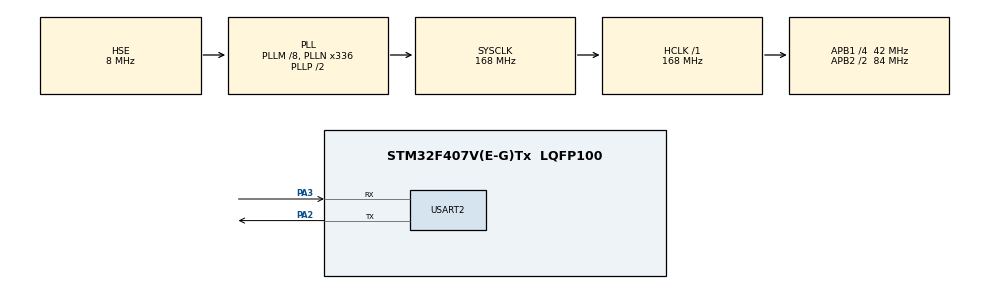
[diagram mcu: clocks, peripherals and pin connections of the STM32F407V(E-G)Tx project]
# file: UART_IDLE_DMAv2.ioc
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Dma.Request0=USART2_RX
Dma.Request1=USART2_TX
Dma.USART2_RX.0.Direction=DMA_PERIPH_TO_MEMORY
Dma.USART2_RX.0.FIFOMode=DMA_FIFOMODE_DISABLE
Dma.USART2_RX.0.Instance=DMA1_Stream5
Dma.USART2_RX.0.MemDataAlignment=DMA_MDATAALIGN_BYTE
Dma.USART2_RX.0.MemInc=DMA_MINC_ENABLE
Dma.USART2_RX.0.Mode=DMA_CIRCULAR
Dma.USART2_RX.0.PeriphDataAlignment=DMA_PDATAALIGN_BYTE
Dma.USART2_RX.0.PeriphInc=DMA_PINC_DISABLE
Dma.USART2_RX.0.Priority=DMA_PRIORITY_LOW
Dma.USART2_TX.1.Direction=DMA_MEMORY_TO_PERIPH
Dma.USART2_TX.1.FIFOMode=DMA_FIFOMODE_DISABLE
Dma.USART2_TX.1.Instance=DMA1_Stream6
Dma.USART2_TX.1.MemDataAlignment=DMA_MDATAALIGN_BYTE
Dma.USART2_TX.1.MemInc=DMA_MINC_ENABLE
Dma.USART2_TX.1.Mode=DMA_NORMAL
Dma.USART2_TX.1.PeriphDataAlignment=DMA_PDATAALIGN_BYTE
Dma.USART2_TX.1.PeriphInc=DMA_PINC_DISABLE
Dma.USART2_TX.1.Priority=DMA_PRIORITY_LOW
FREERTOS.Tasks01=defaultTask,24,128,StartDefaultTask,Default,NULL,Dynamic,NULL,NULL
FREERTOS.configUSE_NEWLIB_REENTRANT=1
Mcu.Family=STM32F4
Mcu.Name=STM32F407V(E-G)Tx
Mcu.Package=LQFP100
NVIC.DMA1_Stream5_IRQn=true\:5\:0\:false\:false\:true\:true\:false\:true\:true
NVIC.DMA1_Stream6_IRQn=true\:5\:0\:false\:false\:true\:true\:false\:true\:true
NVIC.PriorityGroup=NVIC_PRIORITYGROUP_4
NVIC.TIM6_DAC_IRQn=true\:15\:0\:false\:false\:true\:false\:false\:true\:true
NVIC.TimeBase=TIM6_DAC_IRQn
NVIC.TimeBaseIP=TIM6
NVIC.USART2_IRQn=true\:5\:0\:false\:false\:true\:true\:true\:true\:true
PA13.Mode=Serial_Wire
PA13.Signal=SYS_JTMS-SWDIO
PA14.Mode=Serial_Wire
PA14.Signal=SYS_JTCK-SWCLK
PA2.Mode=Asynchronous
PA2.Signal=USART2_TX
PA3.Mode=Asynchronous
PA3.Signal=USART2_RX
PH0-OSC_IN.Mode=HSE-External-Oscillator
PH0-OSC_IN.Signal=RCC_OSC_IN
PH1-OSC_OUT.Mode=HSE-External-Oscillator
PH1-OSC_OUT.Signal=RCC_OSC_OUT
ProjectManager.HeapSize=0x200
ProjectManager.StackSize=0x400
ProjectManager.TargetToolchain=STM32CubeIDE
RCC.48MHZClocksFreq_Value=48000000
RCC.AHBFreq_Value=168000000
RCC.APB1CLKDivider=RCC_HCLK_DIV4
RCC.APB1Freq_Value=42000000
RCC.APB1TimFreq_Value=84000000
RCC.APB2CLKDivider=RCC_HCLK_DIV2
RCC.APB2Freq_Value=84000000
RCC.APB2TimFreq_Value=168000000
RCC.CortexFreq_Value=168000000
RCC.HCLKFreq_Value=168000000
RCC.HSE_VALUE=8000000
RCC.HSI_VALUE=16000000
RCC.LSE_VALUE=32768
RCC.PLLM=8
RCC.PLLN=336
RCC.PLLQ=7
RCC.PLLSourceVirtual=RCC_PLLSOURCE_HSE
RCC.SYSCLKFreq_VALUE=168000000
RCC.SYSCLKSource=RCC_SYSCLKSOURCE_PLLCLK
RCC.VCOOutputFreq_Value=336000000
USART2.VirtualMode=VM_ASYNC
VP_FREERTOS_VS_CMSIS_V2.Mode=CMSIS_V2
VP_SYS_VS_tim6.Mode=TIM6
board=STM32F407G-DISC1

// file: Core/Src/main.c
/* USER CODE BEGIN Header */
/**
  ******************************************************************************
  * @file           : main.c
  * @brief          : Main program body
  ******************************************************************************
  * @attention
  *
  * Copyright (c) 2026 STMicroelectronics.
  * All rights reserved.
  *
  * This software is licensed under terms that can be found in the LICENSE file
  * in the root directory of this software component.
  * If no LICENSE file comes with this software, it is provided AS-IS.
  *
  ******************************************************************************
  */
/* USER CODE END Header */
#include "main.h"
#include "cmsis_os.h"

/* USER CODE BEGIN Includes */
#include "uart_comm.h"
#include "app_protocol.h"
#include "protocol_uart.h"
#ifdef UART_COMM_TEST
#include "uart_comm_internal.h"
#include "tests.h"
#include "uart_comm_tests.h"
#include "uart_rtos_tests.h"
#endif
/* USER CODE END Includes */

UART_HandleTypeDef huart2;
DMA_HandleTypeDef hdma_usart2_rx;
DMA_HandleTypeDef hdma_usart2_tx;

/* Definitions for defaultTask */
osThreadId_t defaultTaskHandle;
const osThreadAttr_t defaultTask_attributes = {
  .name = "defaultTask",
  .stack_size = 128 * 4,
  .priority = (osPriority_t) osPriorityNormal,
};
/* USER CODE BEGIN PV */
uart_comm_tx_result_t uart_last_tx_result;
uint32_t uart_tx_result_count;
#ifdef UART_COMM_TEST
HAL_StatusTypeDef rx_start_status;
#endif
/* USER CODE END PV */

void SystemClock_Config(void);
static void MX_GPIO_Init(void);
static void MX_DMA_Init(void);
static void MX_USART2_UART_Init(void);
void StartDefaultTask(void *argument);

/* USER CODE BEGIN 0 */
#ifndef UART_COMM_TEST
/* Iki handler da UART taskinda calisir: kisa tut, bekleme yapma. */
static void on_tx_result(const uart_comm_tx_result_t *result, void *user)
{
    (void)user;
    uart_last_tx_result = *result;
    uart_tx_result_count++;
}
static protocol_uart_t uart_protocol;
static const uart_comm_handlers_t uart_handlers = {
    .on_rx = protocol_uart_on_rx, .on_tx_result = on_tx_result, .rx_user = &uart_protocol
};
#endif
/* Proje HAL callback'lerinin sahibi; diger UART'lar burada yonlendirilebilir. */
void HAL_UARTEx_RxEventCallback(UART_HandleTypeDef *uart, uint16_t size) { uart_comm_on_rx_event(uart, size); }
void HAL_UART_ErrorCallback(UART_HandleTypeDef *uart) { uart_comm_on_error(uart); }
void HAL_UART_AbortReceiveCpltCallback(UART_HandleTypeDef *uart) { uart_comm_on_rx_abort_complete(uart); }
void HAL_UART_TxCpltCallback(UART_HandleTypeDef *uart) { uart_comm_on_tx_complete(uart); }
void HAL_UART_AbortTransmitCpltCallback(UART_HandleTypeDef *uart) { uart_comm_on_tx_abort_complete(uart); }
/* USER CODE END 0 */

int main(void)
{

  /* MCU Configuration--------------------------------------------------------*/

  /* Reset of all peripherals, Initializes the Flash interface and the Systick. */
  HAL_Init();

  /* Configure the system clock */
  SystemClock_Config();

  /* Initialize all configured peripherals */
  MX_GPIO_Init();
  MX_DMA_Init();
  MX_USART2_UART_Init();
  /* USER CODE BEGIN 2 */
#if defined(UART_COMM_TEST) && !defined(UART_COMM_SERIAL_TEST)
  /* Eski cekirdek regresyonu scheduler oncesi; uretimde bu kapilar yok. */
  birim_testleri_kosur();
  app_protocol_init();
  test_rx_set_handler(app_protocol_on_frame, NULL);
  rx_start_status = rx_start(&huart2);
  if (tx_init(&huart2) != HAL_OK) Error_Handler();
  loopback_testi_kosur(&huart2);
  uart_comm_tests_run(&huart2);
  comm_test_stop_before_scheduler();
#endif
  app_protocol_init();
#ifndef UART_COMM_TEST
  protocol_uart_init(&uart_protocol, app_protocol_on_frame, NULL);
#endif
/* USER CODE END 2 */

  /* Init scheduler */
  osKernelInitialize();

  /* Create the thread(s) */
  /* creation of defaultTask */
  defaultTaskHandle = osThreadNew(StartDefaultTask, NULL, &defaultTask_attributes);

  /* USER CODE BEGIN RTOS_THREADS */
#ifdef UART_COMM_SERIAL_TEST
  uart_serial_test_init_handlers();
  if (uart_comm_init(&huart2, &uart_serial_test_handlers) != HAL_OK) Error_Handler();
#elif defined(UART_COMM_TEST)
  uart_rtos_test_init_handlers();
  if (uart_comm_init(&huart2, &uart_rtos_test_handlers) != HAL_OK) Error_Handler();
#else
  if (uart_comm_init(&huart2, &uart_handlers) != HAL_OK) Error_Handler();
#endif
/* USER CODE END RTOS_THREADS */

  /* Start scheduler */
  osKernelStart();

  /* We should never get here as control is now taken by the scheduler */

  /* Infinite loop */
  while (1)
  {

  /* USER CODE BEGIN 3 */
  Error_Handler();
  }
/* USER CODE END 3 */
}

void SystemClock_Config(void)
{
  RCC_OscInitTypeDef RCC_OscInitStruct = {0};
  RCC_ClkInitTypeDef RCC_ClkInitStruct = {0};

  /** Configure the main internal regulator output voltage
  */
  __HAL_RCC_PWR_CLK_ENABLE();
  __HAL_PWR_VOLTAGESCALING_CONFIG(PWR_REGULATOR_VOLTAGE_SCALE1);

  /** Initializes the RCC Oscillators according to the specified parameters
  * in the RCC_OscInitTypeDef structure.
  */
  RCC_OscInitStruct.OscillatorType = RCC_OSCILLATORTYPE_HSE;
  RCC_OscInitStruct.HSEState = RCC_HSE_ON;
  RCC_OscInitStruct.PLL.PLLState = RCC_PLL_ON;
  RCC_OscInitStruct.PLL.PLLSource = RCC_PLLSOURCE_HSE;
  RCC_OscInitStruct.PLL.PLLM = 8;
  RCC_OscInitStruct.PLL.PLLN = 336;
  RCC_OscInitStruct.PLL.PLLP = RCC_PLLP_DIV2;
  RCC_OscInitStruct.PLL.PLLQ = 7;
  if (HAL_RCC_OscConfig(&RCC_OscInitStruct) != HAL_OK)
  {
    Error_Handler();
  }

  /** Initializes the CPU, AHB and APB buses clocks
  */
  RCC_ClkInitStruct.ClockType = RCC_CLOCKTYPE_HCLK|RCC_CLOCKTYPE_SYSCLK
                              |RCC_CLOCKTYPE_PCLK1|RCC_CLOCKTYPE_PCLK2;
  RCC_ClkInitStruct.SYSCLKSource = RCC_SYSCLKSOURCE_PLLCLK;
  RCC_ClkInitStruct.AHBCLKDivider = RCC_SYSCLK_DIV1;
  RCC_ClkInitStruct.APB1CLKDivider = RCC_HCLK_DIV4;
  RCC_ClkInitStruct.APB2CLKDivider = RCC_HCLK_DIV2;

  if (HAL_RCC_ClockConfig(&RCC_ClkInitStruct, FLASH_LATENCY_5) != HAL_OK)
  {
    Error_Handler();
  }
}

static void MX_USART2_UART_Init(void)
{

  huart2.Instance = USART2;
  huart2.Init.BaudRate = 115200;
  huart2.Init.WordLength = UART_WORDLENGTH_8B;
  huart2.Init.StopBits = UART_STOPBITS_1;
  huart2.Init.Parity = UART_PARITY_NONE;
  huart2.Init.Mode = UART_MODE_TX_RX;
  huart2.Init.HwFlowCtl = UART_HWCONTROL_NONE;
  huart2.Init.OverSampling = UART_OVERSAMPLING_16;
  if (HAL_UART_Init(&huart2) != HAL_OK)
  {
    Error_Handler();
  }

}

static void MX_DMA_Init(void)
{

  /* DMA controller clock enable */
  __HAL_RCC_DMA1_CLK_ENABLE();

  /* DMA interrupt init */
  /* DMA1_Stream5_IRQn interrupt configuration */
  HAL_NVIC_SetPriority(DMA1_Stream5_IRQn, 5, 0);
  HAL_NVIC_EnableIRQ(DMA1_Stream5_IRQn);
  /* DMA1_Stream6_IRQn interrupt configuration */
  HAL_NVIC_SetPriority(DMA1_Stream6_IRQn, 5, 0);
  HAL_NVIC_EnableIRQ(DMA1_Stream6_IRQn);

}

static void MX_GPIO_Init(void)
{

  /* GPIO Ports Clock Enable */
  __HAL_RCC_GPIOH_CLK_ENABLE();
  __HAL_RCC_GPIOA_CLK_ENABLE();

}

void StartDefaultTask(void *argument)
{
  /* USER CODE BEGIN 5 */
  (void)argument;
#ifdef UART_COMM_SERIAL_TEST
  uart_serial_tests_start();
#elif defined(UART_COMM_TEST)
  uart_rtos_tests_start();
#endif
  /* Uygulama buraya kendi isini ekleyebilir. Bos task periyodik uyanmaz. */
  for (;;) vTaskSuspend(NULL);
/* USER CODE END 5 */
}

void HAL_TIM_PeriodElapsedCallback(TIM_HandleTypeDef *htim)
{
  if (htim->Instance == TIM6)
  {
    HAL_IncTick();
  }
}

void Error_Handler(void)
{
  __disable_irq();
  while (1)
  {
  }
}
